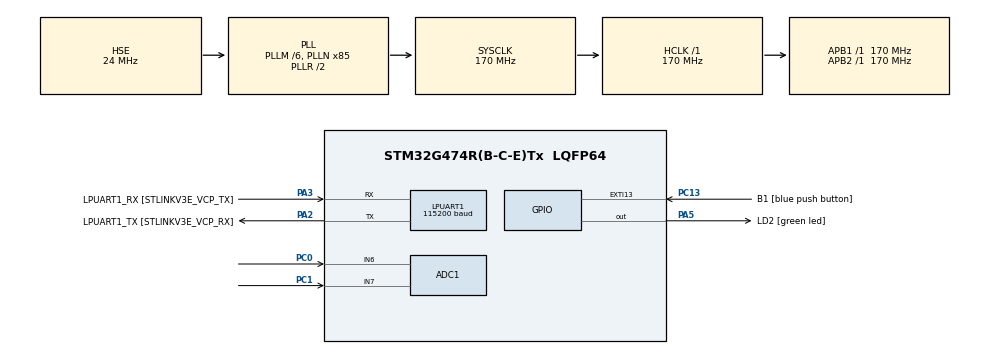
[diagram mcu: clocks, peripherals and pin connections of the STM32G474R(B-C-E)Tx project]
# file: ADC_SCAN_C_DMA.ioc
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ADC1.Channel-0\#ChannelRegularConversion=ADC_CHANNEL_6
ADC1.Channel-1\#ChannelRegularConversion=ADC_CHANNEL_7
ADC1.ContinuousConvMode=ENABLE
ADC1.DMAContinuousRequests=ENABLE
ADC1.NbrOfConversion=2
ADC1.NbrOfConversionFlag=1
ADC1.OffsetNumber-0\#ChannelRegularConversion=ADC_OFFSET_NONE
ADC1.OffsetNumber-1\#ChannelRegularConversion=ADC_OFFSET_NONE
ADC1.Rank-0\#ChannelRegularConversion=1
ADC1.Rank-1\#ChannelRegularConversion=2
ADC1.SamplingTime-0\#ChannelRegularConversion=ADC_SAMPLETIME_47CYCLES_5
ADC1.SamplingTime-1\#ChannelRegularConversion=ADC_SAMPLETIME_47CYCLES_5
ADC1.master=1
Dma.ADC1.0.Direction=DMA_PERIPH_TO_MEMORY
Dma.ADC1.0.EventEnable=DISABLE
Dma.ADC1.0.Instance=DMA1_Channel1
Dma.ADC1.0.MemDataAlignment=DMA_MDATAALIGN_WORD
Dma.ADC1.0.MemInc=DMA_MINC_ENABLE
Dma.ADC1.0.Mode=DMA_CIRCULAR
Dma.ADC1.0.PeriphDataAlignment=DMA_PDATAALIGN_WORD
Dma.ADC1.0.PeriphInc=DMA_PINC_DISABLE
Dma.ADC1.0.Polarity=HAL_DMAMUX_REQ_GEN_RISING
Dma.ADC1.0.Priority=DMA_PRIORITY_LOW
Dma.ADC1.0.RequestNumber=1
Dma.ADC1.0.SignalID=NONE
Dma.ADC1.0.SyncEnable=DISABLE
Dma.ADC1.0.SyncPolarity=HAL_DMAMUX_SYNC_NO_EVENT
Dma.ADC1.0.SyncRequestNumber=1
Dma.ADC1.0.SyncSignalID=NONE
Dma.Request0=ADC1
LPUART1.BaudRate=115200
LPUART1.WordLength=UART_WORDLENGTH_8B
Mcu.Family=STM32G4
Mcu.Name=STM32G474R(B-C-E)Tx
Mcu.Package=LQFP64
NVIC.DMA1_Channel1_IRQn=true\:0\:0\:false\:false\:true\:false\:true
NVIC.EXTI15_10_IRQn=true\:0\:0\:false\:false\:true\:true\:true
NVIC.PriorityGroup=NVIC_PRIORITYGROUP_4
PA13.GPIO_Label=T_SWDIO
PA13.Mode=Serial_Wire
PA13.Signal=SYS_JTMS-SWDIO
PA14.GPIO_Label=T_SWCLK
PA14.Mode=Serial_Wire
PA14.Signal=SYS_JTCK-SWCLK
PA2.GPIO_Label=LPUART1_TX [STLINKV3E_VCP_RX]
PA2.Mode=Asynchronous
PA2.Signal=LPUART1_TX
PA3.GPIO_Label=LPUART1_RX [STLINKV3E_VCP_TX]
PA3.Mode=Asynchronous
PA3.Signal=LPUART1_RX
PA5.GPIO_Label=LD2 [green led]
PA5.Signal=GPIO_Output
PB3.GPIO_Label=T_SWO
PB3.Signal=SYS_JTDO-SWO
PC0.Mode=IN6-Single-Ended
PC0.Signal=ADC1_IN6
PC1.Mode=IN7-Single-Ended
PC1.Signal=ADC1_IN7
PC13.GPIO_Label=B1 [blue push button]
PC13.Signal=GPXTI13
PC14-OSC32_IN.Mode=LSE-External-Oscillator
PC14-OSC32_IN.Signal=RCC_OSC32_IN
PC15-OSC32_OUT.Mode=LSE-External-Oscillator
PC15-OSC32_OUT.Signal=RCC_OSC32_OUT
PF0-OSC_IN.Mode=HSE-External-Oscillator
PF0-OSC_IN.Signal=RCC_OSC_IN
PF1-OSC_OUT.Mode=HSE-External-Oscillator
PF1-OSC_OUT.Signal=RCC_OSC_OUT
ProjectManager.HeapSize=0x200
ProjectManager.StackSize=0x400
ProjectManager.TargetToolchain=STM32CubeIDE
RCC.ADC12Freq_Value=170000000
RCC.ADC345Freq_Value=170000000
RCC.AHBFreq_Value=170000000
RCC.APB1Freq_Value=170000000
RCC.APB1TimFreq_Value=170000000
RCC.APB2Freq_Value=170000000
RCC.APB2TimFreq_Value=170000000
RCC.CortexFreq_Value=170000000
RCC.EXTERNAL_CLOCK_VALUE=12288000
RCC.HCLKFreq_Value=170000000
RCC.HSE_VALUE=24000000
RCC.HSI48_VALUE=48000000
RCC.HSI_VALUE=16000000
RCC.PLLM=RCC_PLLM_DIV6
RCC.PLLN=85
RCC.PLLSourceVirtual=RCC_PLLSOURCE_HSE
RCC.RTCClockSelection=RCC_RTCCLKSOURCE_LSE
RCC.SYSCLKFreq_VALUE=170000000
RCC.SYSCLKSource=RCC_SYSCLKSOURCE_PLLCLK
RCC.USBFreq_Value=170000000
RCC.VCOOutputFreq_Value=340000000
VP_SYS_VS_DBSignals.Mode=DisableDeadBatterySignals
board=NUCLEO-G474RE

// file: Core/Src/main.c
/* USER CODE BEGIN Header */
/**
  ******************************************************************************
  * @file           : main.c
  * @brief          : Main program body
  ******************************************************************************
  * @attention
  *
  * <h2><center>&copy; Copyright (c) 2021 STMicroelectronics.
  * All rights reserved.</center></h2>
  *
  * This software component is licensed by ST under BSD 3-Clause license,
  * the "License"; You may not use this file except in compliance with the
  * License. You may obtain a copy of the License at:
  *                        opensource.org/licenses/BSD-3-Clause
  *
  ******************************************************************************
  */
/* USER CODE END Header */
#include "main.h"
#include "adc.h"
#include "dma.h"
#include "usart.h"
#include "gpio.h"

/* USER CODE BEGIN PV */
volatile uint32_t ADC_Value[2];

//void HAL_ADC_ConvCpltCallback(ADC_HandleTypeDef* hadc)
//{
//
//  HAL_ADC_Start_DMA(&hadc1,(uint32_t *)ADC_Value,sizeof(ADC_Value)/sizeof(ADC_Value[0]));
//
//}
/* USER CODE END PV */

void SystemClock_Config(void);

int main(void)
{

  /* MCU Configuration--------------------------------------------------------*/

  /* Reset of all peripherals, Initializes the Flash interface and the Systick. */
  HAL_Init();

  /* Configure the system clock */
  SystemClock_Config();

  /* Initialize all configured peripherals */
  MX_GPIO_Init();
  MX_LPUART1_UART_Init();
  MX_DMA_Init();
  MX_ADC1_Init();
  /* USER CODE BEGIN 2 */

  HAL_ADC_Start_DMA(&hadc1,(uint32_t *)ADC_Value,sizeof(ADC_Value)/sizeof(ADC_Value[0]));

  /* USER CODE END 2 */

  /* Infinite loop */
  while (1)
  {

    /* USER CODE BEGIN 3 */

		HAL_Delay(2000);
		printf(" %lu %lu\r\n",ADC_Value[0],ADC_Value[1]);//这里为了�???????单演示，�???????以在中断回调里面直接打印�???????
  }
  /* USER CODE END 3 */
}

void SystemClock_Config(void)
{
  RCC_OscInitTypeDef RCC_OscInitStruct = {0};
  RCC_ClkInitTypeDef RCC_ClkInitStruct = {0};
  RCC_PeriphCLKInitTypeDef PeriphClkInit = {0};

  /** Configure the main internal regulator output voltage
  */
  HAL_PWREx_ControlVoltageScaling(PWR_REGULATOR_VOLTAGE_SCALE1_BOOST);
  /** Initializes the RCC Oscillators according to the specified parameters
  * in the RCC_OscInitTypeDef structure.
  */
  RCC_OscInitStruct.OscillatorType = RCC_OSCILLATORTYPE_HSE;
  RCC_OscInitStruct.HSEState = RCC_HSE_ON;
  RCC_OscInitStruct.PLL.PLLState = RCC_PLL_ON;
  RCC_OscInitStruct.PLL.PLLSource = RCC_PLLSOURCE_HSE;
  RCC_OscInitStruct.PLL.PLLM = RCC_PLLM_DIV6;
  RCC_OscInitStruct.PLL.PLLN = 85;
  RCC_OscInitStruct.PLL.PLLP = RCC_PLLP_DIV2;
  RCC_OscInitStruct.PLL.PLLQ = RCC_PLLQ_DIV2;
  RCC_OscInitStruct.PLL.PLLR = RCC_PLLR_DIV2;
  if (HAL_RCC_OscConfig(&RCC_OscInitStruct) != HAL_OK)
  {
    Error_Handler();
  }
  /** Initializes the CPU, AHB and APB buses clocks
  */
  RCC_ClkInitStruct.ClockType = RCC_CLOCKTYPE_HCLK|RCC_CLOCKTYPE_SYSCLK
                              |RCC_CLOCKTYPE_PCLK1|RCC_CLOCKTYPE_PCLK2;
  RCC_ClkInitStruct.SYSCLKSource = RCC_SYSCLKSOURCE_PLLCLK;
  RCC_ClkInitStruct.AHBCLKDivider = RCC_SYSCLK_DIV1;
  RCC_ClkInitStruct.APB1CLKDivider = RCC_HCLK_DIV1;
  RCC_ClkInitStruct.APB2CLKDivider = RCC_HCLK_DIV1;

  if (HAL_RCC_ClockConfig(&RCC_ClkInitStruct, FLASH_LATENCY_4) != HAL_OK)
  {
    Error_Handler();
  }
  /** Initializes the peripherals clocks
  */
  PeriphClkInit.PeriphClockSelection = RCC_PERIPHCLK_LPUART1|RCC_PERIPHCLK_ADC12;
  PeriphClkInit.Lpuart1ClockSelection = RCC_LPUART1CLKSOURCE_PCLK1;
  PeriphClkInit.Adc12ClockSelection = RCC_ADC12CLKSOURCE_SYSCLK;
  if (HAL_RCCEx_PeriphCLKConfig(&PeriphClkInit) != HAL_OK)
  {
    Error_Handler();
  }
}

void Error_Handler(void)
{
  __disable_irq();
  while (1)
  {
  }
}

/************************ (C) COPYRIGHT STMicroelectronics *****END OF FILE****/
